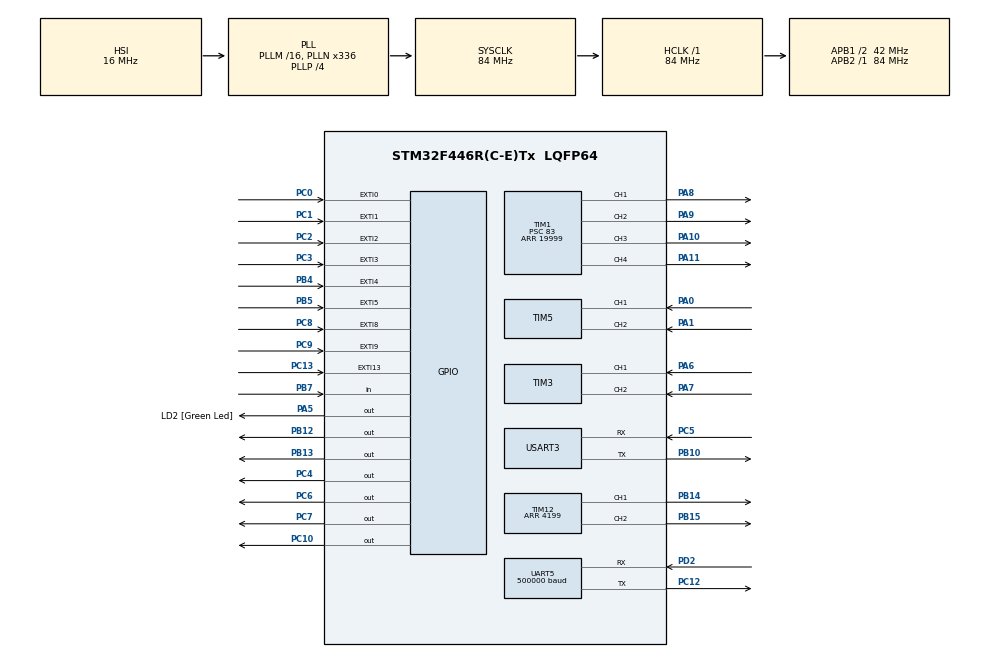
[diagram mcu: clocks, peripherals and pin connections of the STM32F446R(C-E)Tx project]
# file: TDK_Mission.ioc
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Dma.Request0=USART3_RX
Dma.Request1=USART3_TX
Dma.USART3_RX.0.Direction=DMA_PERIPH_TO_MEMORY
Dma.USART3_RX.0.FIFOMode=DMA_FIFOMODE_DISABLE
Dma.USART3_RX.0.Instance=DMA1_Stream1
Dma.USART3_RX.0.MemDataAlignment=DMA_MDATAALIGN_BYTE
Dma.USART3_RX.0.MemInc=DMA_MINC_ENABLE
Dma.USART3_RX.0.Mode=DMA_NORMAL
Dma.USART3_RX.0.PeriphDataAlignment=DMA_PDATAALIGN_BYTE
Dma.USART3_RX.0.PeriphInc=DMA_PINC_DISABLE
Dma.USART3_RX.0.Priority=DMA_PRIORITY_LOW
Dma.USART3_TX.1.Direction=DMA_MEMORY_TO_PERIPH
Dma.USART3_TX.1.FIFOMode=DMA_FIFOMODE_DISABLE
Dma.USART3_TX.1.Instance=DMA1_Stream3
Dma.USART3_TX.1.MemDataAlignment=DMA_MDATAALIGN_BYTE
Dma.USART3_TX.1.MemInc=DMA_MINC_ENABLE
Dma.USART3_TX.1.Mode=DMA_NORMAL
Dma.USART3_TX.1.PeriphDataAlignment=DMA_PDATAALIGN_BYTE
Dma.USART3_TX.1.PeriphInc=DMA_PINC_DISABLE
Dma.USART3_TX.1.Priority=DMA_PRIORITY_LOW
Mcu.Family=STM32F4
Mcu.Name=STM32F446R(C-E)Tx
Mcu.Package=LQFP64
NVIC.DMA1_Stream1_IRQn=true\:0\:0\:false\:false\:true\:false\:true\:true
NVIC.DMA1_Stream3_IRQn=true\:0\:0\:false\:false\:true\:false\:true\:true
NVIC.EXTI0_IRQn=true\:0\:0\:true\:true\:true\:1\:true\:true\:true
NVIC.EXTI15_10_IRQn=true\:0\:0\:false\:false\:true\:true\:true\:true
NVIC.EXTI1_IRQn=true\:0\:0\:false\:true\:true\:2\:true\:true\:true
NVIC.EXTI2_IRQn=true\:0\:0\:false\:false\:true\:true\:true\:true
NVIC.EXTI3_IRQn=true\:0\:0\:false\:false\:true\:true\:true\:true
NVIC.EXTI4_IRQn=true\:0\:0\:false\:true\:true\:3\:true\:true\:true
NVIC.EXTI9_5_IRQn=true\:0\:0\:false\:true\:true\:4\:true\:true\:true
NVIC.PriorityGroup=NVIC_PRIORITYGROUP_0
NVIC.TIM1_BRK_TIM9_IRQn=true\:0\:0\:false\:true\:true\:5\:true\:true\:true
NVIC.TIM1_TRG_COM_TIM11_IRQn=true\:0\:0\:false\:false\:true\:true\:true\:true
NVIC.TIM1_UP_TIM10_IRQn=true\:0\:0\:false\:true\:true\:6\:true\:true\:true
NVIC.TIM2_IRQn=true\:0\:0\:false\:false\:true\:true\:true\:true
NVIC.TIM7_IRQn=true\:0\:0\:false\:true\:true\:7\:true\:true\:true
NVIC.TIM8_UP_TIM13_IRQn=true\:0\:0\:false\:false\:true\:true\:true\:true
NVIC.USART3_IRQn=true\:0\:0\:false\:false\:true\:true\:true\:true
PA0-WKUP.Signal=S_TIM5_CH1
PA1.Signal=S_TIM5_CH2
PA10.Signal=S_TIM1_CH3
PA11.Signal=S_TIM1_CH4
PA13.GPIO_Label=TMS
PA13.Mode=Serial_Wire
PA13.Signal=SYS_JTMS-SWDIO
PA14.GPIO_Label=TCK
PA14.Mode=Serial_Wire
PA14.Signal=SYS_JTCK-SWCLK
PA2.Signal=USART2_TX
PA3.Signal=USART2_RX
PA5.GPIO_Label=LD2 [Green Led]
PA5.GPIO_PuPd=GPIO_NOPULL
PA5.Signal=GPIO_Output
PA6.Signal=S_TIM3_CH1
PA7.Signal=S_TIM3_CH2
PA8.Signal=S_TIM1_CH1
PA9.Signal=S_TIM1_CH2
PB10.Mode=Asynchronous
PB10.Signal=USART3_TX
PB12.GPIO_PuPd=GPIO_NOPULL
PB12.Signal=GPIO_Output
PB13.GPIO_PuPd=GPIO_NOPULL
PB13.Signal=GPIO_Output
PB14.Signal=S_TIM12_CH1
PB15.Signal=S_TIM12_CH2
PB3.GPIO_Label=SWO
PB3.Signal=SYS_JTDO-SWO
PB4.GPIO_ModeDefaultEXTI=GPIO_MODE_IT_RISING
PB4.GPIO_PuPd=GPIO_PULLDOWN
PB4.Signal=GPXTI4
PB5.GPIO_ModeDefaultEXTI=GPIO_MODE_IT_RISING
PB5.GPIO_PuPd=GPIO_PULLDOWN
PB5.Signal=GPXTI5
PB7.GPIO_PuPd=GPIO_PULLUP
PB7.Signal=GPIO_Input
PC0.GPIO_ModeDefaultEXTI=GPIO_MODE_IT_RISING
PC0.GPIO_PuPd=GPIO_PULLDOWN
PC0.Signal=GPXTI0
PC1.GPIO_ModeDefaultEXTI=GPIO_MODE_IT_RISING
PC1.GPIO_PuPd=GPIO_PULLDOWN
PC1.Signal=GPXTI1
PC10.Signal=GPIO_Output
PC12.Mode=Asynchronous
PC12.Signal=UART5_TX
PC13.GPIO_ModeDefaultEXTI=GPIO_MODE_IT_FALLING
PC13.GPIO_PuPd=GPIO_PULLUP
PC13.Signal=GPXTI13
PC14-OSC32_IN.Mode=LSE-External-Oscillator
PC14-OSC32_IN.Signal=RCC_OSC32_IN
PC15-OSC32_OUT.Mode=LSE-External-Oscillator
PC15-OSC32_OUT.Signal=RCC_OSC32_OUT
PC2.GPIO_ModeDefaultEXTI=GPIO_MODE_IT_FALLING
PC2.GPIO_PuPd=GPIO_PULLUP
PC2.Signal=GPXTI2
PC3.GPIO_ModeDefaultEXTI=GPIO_MODE_IT_FALLING
PC3.GPIO_PuPd=GPIO_PULLUP
PC3.Signal=GPXTI3
PC4.Signal=GPIO_Output
PC5.Mode=Asynchronous
PC5.Signal=USART3_RX
PC6.Signal=GPIO_Output
PC7.Signal=GPIO_Output
PC8.GPIO_ModeDefaultEXTI=GPIO_MODE_IT_FALLING
PC8.GPIO_PuPd=GPIO_PULLUP
PC8.Signal=GPXTI8
PC9.Signal=GPXTI9
PD2.Mode=Asynchronous
PD2.Signal=UART5_RX
PH0-OSC_IN.Mode=HSE-External-Oscillator
PH0-OSC_IN.Signal=RCC_OSC_IN
PH1-OSC_OUT.Mode=HSE-External-Oscillator
PH1-OSC_OUT.Signal=RCC_OSC_OUT
ProjectManager.HeapSize=0x200
ProjectManager.StackSize=0x400
ProjectManager.TargetToolchain=STM32CubeIDE
RCC.48MHZClocksFreq_Value=84000000
RCC.AHBFreq_Value=84000000
RCC.APB1CLKDivider=RCC_HCLK_DIV2
RCC.APB1Freq_Value=42000000
RCC.APB1TimFreq_Value=84000000
RCC.APB2Freq_Value=84000000
RCC.APB2TimFreq_Value=84000000
RCC.CortexFreq_Value=84000000
RCC.FLatency-AdvancedSettings=FLASH_LATENCY_2
RCC.HCLKFreq_Value=84000000
RCC.HSE_VALUE=8000000
RCC.HSI_VALUE=16000000
RCC.PLLN=336
RCC.PLLP=RCC_PLLP_DIV4
RCC.SYSCLKFreq_VALUE=84000000
RCC.SYSCLKSource=RCC_SYSCLKSOURCE_PLLCLK
RCC.USBFreq_Value=168000000
RCC.VCOOutputFreq_Value=336000000
SH.S_TIM12_CH1.0=TIM12_CH1,PWM Generation1 CH1
SH.S_TIM12_CH2.0=TIM12_CH2,PWM Generation2 CH2
SH.S_TIM1_CH1.0=TIM1_CH1,PWM Generation1 CH1
SH.S_TIM1_CH2.0=TIM1_CH2,PWM Generation2 CH2
SH.S_TIM1_CH3.0=TIM1_CH3,PWM Generation3 CH3
SH.S_TIM1_CH4.0=TIM1_CH4,PWM Generation4 CH4
SH.S_TIM3_CH1.0=TIM3_CH1,Encoder_Interface
SH.S_TIM3_CH2.0=TIM3_CH2,Encoder_Interface
SH.S_TIM5_CH1.0=TIM5_CH1,Encoder_Interface
SH.S_TIM5_CH2.0=TIM5_CH2,Encoder_Interface
TIM1.Channel-PWM\ Generation1\ CH1=TIM_CHANNEL_1
TIM1.Channel-PWM\ Generation2\ CH2=TIM_CHANNEL_2
TIM1.Channel-PWM\ Generation3\ CH3=TIM_CHANNEL_3
TIM1.Channel-PWM\ Generation4\ CH4=TIM_CHANNEL_4
TIM1.Period=19999
TIM1.Prescaler=83
TIM10.Period=999
TIM10.Prescaler=83
TIM11.Period=999
TIM11.Prescaler=83
TIM12.Channel-PWM\ Generation1\ CH1=TIM_CHANNEL_1
TIM12.Channel-PWM\ Generation2\ CH2=TIM_CHANNEL_2
TIM12.Period=4199
TIM12.Pulse-PWM\ Generation1\ CH1=4000
TIM12.Pulse-PWM\ Generation2\ CH2=4000
TIM13.Period=999
TIM13.Prescaler=83
TIM2.Period=99999
TIM2.Prescaler=83
TIM3.EncoderMode=TIM_ENCODERMODE_TI12
TIM5.EncoderMode=TIM_ENCODERMODE_TI12
TIM7.Period=999
TIM7.Prescaler=83
TIM9.Period=999
TIM9.Prescaler=83
UART5.BaudRate=500000
UART5.VirtualMode=Asynchronous
USART3.VirtualMode=VM_ASYNC
VP_TIM10_VS_ClockSourceINT.Mode=Enable_Timer
VP_TIM11_VS_ClockSourceINT.Mode=Enable_Timer
VP_TIM13_VS_ClockSourceINT.Mode=Enable_Timer
VP_TIM2_VS_ClockSourceINT.Mode=Internal
VP_TIM7_VS_ClockSourceINT.Mode=Enable_Timer
VP_TIM9_VS_ClockSourceINT.Mode=Internal
board=NUCLEO-F446RE

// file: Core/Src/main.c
/* USER CODE BEGIN Header */
/**
  ******************************************************************************
  * @file           : main.c
  * @brief          : Main program body
  ******************************************************************************
  * @attention
  *
  * Copyright (c) 2024 STMicroelectronics.
  * All rights reserved.
  *
  * This software is licensed under terms that can be found in the LICENSE file
  * in the root directory of this software component.
  * If no LICENSE file comes with this software, it is provided AS-IS.
  *
  ******************************************************************************
  */
/* USER CODE END Header */
#include "main.h"

/* USER CODE BEGIN Includes */
#include "mainpp.h"
/* USER CODE END Includes */

TIM_HandleTypeDef htim1;
TIM_HandleTypeDef htim2;
TIM_HandleTypeDef htim3;
TIM_HandleTypeDef htim5;
TIM_HandleTypeDef htim7;
TIM_HandleTypeDef htim9;
TIM_HandleTypeDef htim10;
TIM_HandleTypeDef htim11;
TIM_HandleTypeDef htim12;
TIM_HandleTypeDef htim13;

UART_HandleTypeDef huart5;
UART_HandleTypeDef huart3;
DMA_HandleTypeDef hdma_usart3_rx;
DMA_HandleTypeDef hdma_usart3_tx;

void SystemClock_Config(void);
static void MX_GPIO_Init(void);
static void MX_DMA_Init(void);
static void MX_TIM1_Init(void);
static void MX_TIM3_Init(void);
static void MX_TIM7_Init(void);
static void MX_UART5_Init(void);
static void MX_USART3_UART_Init(void);
static void MX_TIM12_Init(void);
static void MX_TIM10_Init(void);
static void MX_TIM11_Init(void);
static void MX_TIM5_Init(void);
static void MX_TIM2_Init(void);
static void MX_TIM9_Init(void);
static void MX_TIM13_Init(void);
static void MX_NVIC_Init(void);

/* USER CODE BEGIN 0 */
int q = 0;
/* USER CODE END 0 */

int main(void)
{

  /* MCU Configuration--------------------------------------------------------*/

  /* Reset of all peripherals, Initializes the Flash interface and the Systick. */
  HAL_Init();

  /* Configure the system clock */
  SystemClock_Config();

  /* Initialize all configured peripherals */
  MX_GPIO_Init();
  MX_DMA_Init();
  MX_TIM1_Init();
  MX_TIM3_Init();
  MX_TIM7_Init();
  MX_UART5_Init();
  MX_USART3_UART_Init();
  MX_TIM12_Init();
  MX_TIM10_Init();
  MX_TIM11_Init();
  MX_TIM5_Init();
  MX_TIM2_Init();
  MX_TIM9_Init();
  MX_TIM13_Init();

  /* Initialize interrupts */
  MX_NVIC_Init();
  /* USER CODE BEGIN 2 */
  setup();

  main_function();

  /* USER CODE END 2 */

  /* Infinite loop */
  while (1)
  {

  }
}

void SystemClock_Config(void)
{
  RCC_OscInitTypeDef RCC_OscInitStruct = {0};
  RCC_ClkInitTypeDef RCC_ClkInitStruct = {0};

  /** Configure the main internal regulator output voltage
  */
  __HAL_RCC_PWR_CLK_ENABLE();
  __HAL_PWR_VOLTAGESCALING_CONFIG(PWR_REGULATOR_VOLTAGE_SCALE3);

  /** Initializes the RCC Oscillators according to the specified parameters
  * in the RCC_OscInitTypeDef structure.
  */
  RCC_OscInitStruct.OscillatorType = RCC_OSCILLATORTYPE_HSI;
  RCC_OscInitStruct.HSIState = RCC_HSI_ON;
  RCC_OscInitStruct.HSICalibrationValue = RCC_HSICALIBRATION_DEFAULT;
  RCC_OscInitStruct.PLL.PLLState = RCC_PLL_ON;
  RCC_OscInitStruct.PLL.PLLSource = RCC_PLLSOURCE_HSI;
  RCC_OscInitStruct.PLL.PLLM = 16;
  RCC_OscInitStruct.PLL.PLLN = 336;
  RCC_OscInitStruct.PLL.PLLP = RCC_PLLP_DIV4;
  RCC_OscInitStruct.PLL.PLLQ = 2;
  RCC_OscInitStruct.PLL.PLLR = 2;
  if (HAL_RCC_OscConfig(&RCC_OscInitStruct) != HAL_OK)
  {
    Error_Handler();
  }

  /** Initializes the CPU, AHB and APB buses clocks
  */
  RCC_ClkInitStruct.ClockType = RCC_CLOCKTYPE_HCLK|RCC_CLOCKTYPE_SYSCLK
                              |RCC_CLOCKTYPE_PCLK1|RCC_CLOCKTYPE_PCLK2;
  RCC_ClkInitStruct.SYSCLKSource = RCC_SYSCLKSOURCE_PLLCLK;
  RCC_ClkInitStruct.AHBCLKDivider = RCC_SYSCLK_DIV1;
  RCC_ClkInitStruct.APB1CLKDivider = RCC_HCLK_DIV2;
  RCC_ClkInitStruct.APB2CLKDivider = RCC_HCLK_DIV1;

  if (HAL_RCC_ClockConfig(&RCC_ClkInitStruct, FLASH_LATENCY_2) != HAL_OK)
  {
    Error_Handler();
  }
}

/**
  * @brief NVIC Configuration.
  * @retval None
  */
static void MX_NVIC_Init(void)
{
  /* EXTI0_IRQn interrupt configuration */
  HAL_NVIC_SetPriority(EXTI0_IRQn, 0, 0);
  HAL_NVIC_EnableIRQ(EXTI0_IRQn);
  /* EXTI1_IRQn interrupt configuration */
  HAL_NVIC_SetPriority(EXTI1_IRQn, 0, 0);
  HAL_NVIC_EnableIRQ(EXTI1_IRQn);
  /* EXTI4_IRQn interrupt configuration */
  HAL_NVIC_SetPriority(EXTI4_IRQn, 0, 0);
  HAL_NVIC_EnableIRQ(EXTI4_IRQn);
  /* EXTI9_5_IRQn interrupt configuration */
  HAL_NVIC_SetPriority(EXTI9_5_IRQn, 0, 0);
  HAL_NVIC_EnableIRQ(EXTI9_5_IRQn);
  /* TIM1_BRK_TIM9_IRQn interrupt configuration */
  HAL_NVIC_SetPriority(TIM1_BRK_TIM9_IRQn, 0, 0);
  HAL_NVIC_EnableIRQ(TIM1_BRK_TIM9_IRQn);
  /* TIM1_UP_TIM10_IRQn interrupt configuration */
  HAL_NVIC_SetPriority(TIM1_UP_TIM10_IRQn, 0, 0);
  HAL_NVIC_EnableIRQ(TIM1_UP_TIM10_IRQn);
  /* TIM7_IRQn interrupt configuration */
  HAL_NVIC_SetPriority(TIM7_IRQn, 0, 0);
  HAL_NVIC_EnableIRQ(TIM7_IRQn);
}

static void MX_TIM1_Init(void)
{

  TIM_MasterConfigTypeDef sMasterConfig = {0};
  TIM_OC_InitTypeDef sConfigOC = {0};
  TIM_BreakDeadTimeConfigTypeDef sBreakDeadTimeConfig = {0};

  htim1.Instance = TIM1;
  htim1.Init.Prescaler = 83;
  htim1.Init.CounterMode = TIM_COUNTERMODE_UP;
  htim1.Init.Period = 19999;
  htim1.Init.ClockDivision = TIM_CLOCKDIVISION_DIV1;
  htim1.Init.RepetitionCounter = 0;
  htim1.Init.AutoReloadPreload = TIM_AUTORELOAD_PRELOAD_DISABLE;
  if (HAL_TIM_PWM_Init(&htim1) != HAL_OK)
  {
    Error_Handler();
  }
  sMasterConfig.MasterOutputTrigger = TIM_TRGO_RESET;
  sMasterConfig.MasterSlaveMode = TIM_MASTERSLAVEMODE_DISABLE;
  if (HAL_TIMEx_MasterConfigSynchronization(&htim1, &sMasterConfig) != HAL_OK)
  {
    Error_Handler();
  }
  sConfigOC.OCMode = TIM_OCMODE_PWM1;
  sConfigOC.Pulse = 0;
  sConfigOC.OCPolarity = TIM_OCPOLARITY_HIGH;
  sConfigOC.OCNPolarity = TIM_OCNPOLARITY_HIGH;
  sConfigOC.OCFastMode = TIM_OCFAST_DISABLE;
  sConfigOC.OCIdleState = TIM_OCIDLESTATE_RESET;
  sConfigOC.OCNIdleState = TIM_OCNIDLESTATE_RESET;
  if (HAL_TIM_PWM_ConfigChannel(&htim1, &sConfigOC, TIM_CHANNEL_1) != HAL_OK)
  {
    Error_Handler();
  }
  if (HAL_TIM_PWM_ConfigChannel(&htim1, &sConfigOC, TIM_CHANNEL_2) != HAL_OK)
  {
    Error_Handler();
  }
  if (HAL_TIM_PWM_ConfigChannel(&htim1, &sConfigOC, TIM_CHANNEL_3) != HAL_OK)
  {
    Error_Handler();
  }
  if (HAL_TIM_PWM_ConfigChannel(&htim1, &sConfigOC, TIM_CHANNEL_4) != HAL_OK)
  {
    Error_Handler();
  }
  sBreakDeadTimeConfig.OffStateRunMode = TIM_OSSR_DISABLE;
  sBreakDeadTimeConfig.OffStateIDLEMode = TIM_OSSI_DISABLE;
  sBreakDeadTimeConfig.LockLevel = TIM_LOCKLEVEL_OFF;
  sBreakDeadTimeConfig.DeadTime = 0;
  sBreakDeadTimeConfig.BreakState = TIM_BREAK_DISABLE;
  sBreakDeadTimeConfig.BreakPolarity = TIM_BREAKPOLARITY_HIGH;
  sBreakDeadTimeConfig.AutomaticOutput = TIM_AUTOMATICOUTPUT_DISABLE;
  if (HAL_TIMEx_ConfigBreakDeadTime(&htim1, &sBreakDeadTimeConfig) != HAL_OK)
  {
    Error_Handler();
  }
  HAL_TIM_MspPostInit(&htim1);

}

static void MX_TIM2_Init(void)
{

  TIM_ClockConfigTypeDef sClockSourceConfig = {0};
  TIM_MasterConfigTypeDef sMasterConfig = {0};

  htim2.Instance = TIM2;
  htim2.Init.Prescaler = 83;
  htim2.Init.CounterMode = TIM_COUNTERMODE_UP;
  htim2.Init.Period = 99999;
  htim2.Init.ClockDivision = TIM_CLOCKDIVISION_DIV1;
  htim2.Init.AutoReloadPreload = TIM_AUTORELOAD_PRELOAD_DISABLE;
  if (HAL_TIM_Base_Init(&htim2) != HAL_OK)
  {
    Error_Handler();
  }
  sClockSourceConfig.ClockSource = TIM_CLOCKSOURCE_INTERNAL;
  if (HAL_TIM_ConfigClockSource(&htim2, &sClockSourceConfig) != HAL_OK)
  {
    Error_Handler();
  }
  sMasterConfig.MasterOutputTrigger = TIM_TRGO_RESET;
  sMasterConfig.MasterSlaveMode = TIM_MASTERSLAVEMODE_DISABLE;
  if (HAL_TIMEx_MasterConfigSynchronization(&htim2, &sMasterConfig) != HAL_OK)
  {
    Error_Handler();
  }

}

static void MX_TIM3_Init(void)
{

  TIM_Encoder_InitTypeDef sConfig = {0};
  TIM_MasterConfigTypeDef sMasterConfig = {0};

  htim3.Instance = TIM3;
  htim3.Init.Prescaler = 0;
  htim3.Init.CounterMode = TIM_COUNTERMODE_UP;
  htim3.Init.Period = 65535;
  htim3.Init.ClockDivision = TIM_CLOCKDIVISION_DIV1;
  htim3.Init.AutoReloadPreload = TIM_AUTORELOAD_PRELOAD_DISABLE;
  sConfig.EncoderMode = TIM_ENCODERMODE_TI12;
  sConfig.IC1Polarity = TIM_ICPOLARITY_RISING;
  sConfig.IC1Selection = TIM_ICSELECTION_DIRECTTI;
  sConfig.IC1Prescaler = TIM_ICPSC_DIV1;
  sConfig.IC1Filter = 0;
  sConfig.IC2Polarity = TIM_ICPOLARITY_RISING;
  sConfig.IC2Selection = TIM_ICSELECTION_DIRECTTI;
  sConfig.IC2Prescaler = TIM_ICPSC_DIV1;
  sConfig.IC2Filter = 0;
  if (HAL_TIM_Encoder_Init(&htim3, &sConfig) != HAL_OK)
  {
    Error_Handler();
  }
  sMasterConfig.MasterOutputTrigger = TIM_TRGO_RESET;
  sMasterConfig.MasterSlaveMode = TIM_MASTERSLAVEMODE_DISABLE;
  if (HAL_TIMEx_MasterConfigSynchronization(&htim3, &sMasterConfig) != HAL_OK)
  {
    Error_Handler();
  }

}

static void MX_TIM5_Init(void)
{

  TIM_Encoder_InitTypeDef sConfig = {0};
  TIM_MasterConfigTypeDef sMasterConfig = {0};

  htim5.Instance = TIM5;
  htim5.Init.Prescaler = 0;
  htim5.Init.CounterMode = TIM_COUNTERMODE_UP;
  htim5.Init.Period = 4294967295;
  htim5.Init.ClockDivision = TIM_CLOCKDIVISION_DIV1;
  htim5.Init.AutoReloadPreload = TIM_AUTORELOAD_PRELOAD_DISABLE;
  sConfig.EncoderMode = TIM_ENCODERMODE_TI12;
  sConfig.IC1Polarity = TIM_ICPOLARITY_RISING;
  sConfig.IC1Selection = TIM_ICSELECTION_DIRECTTI;
  sConfig.IC1Prescaler = TIM_ICPSC_DIV1;
  sConfig.IC1Filter = 0;
  sConfig.IC2Polarity = TIM_ICPOLARITY_RISING;
  sConfig.IC2Selection = TIM_ICSELECTION_DIRECTTI;
  sConfig.IC2Prescaler = TIM_ICPSC_DIV1;
  sConfig.IC2Filter = 0;
  if (HAL_TIM_Encoder_Init(&htim5, &sConfig) != HAL_OK)
  {
    Error_Handler();
  }
  sMasterConfig.MasterOutputTrigger = TIM_TRGO_RESET;
  sMasterConfig.MasterSlaveMode = TIM_MASTERSLAVEMODE_DISABLE;
  if (HAL_TIMEx_MasterConfigSynchronization(&htim5, &sMasterConfig) != HAL_OK)
  {
    Error_Handler();
  }

}

static void MX_TIM7_Init(void)
{

  TIM_MasterConfigTypeDef sMasterConfig = {0};

  htim7.Instance = TIM7;
  htim7.Init.Prescaler = 83;
  htim7.Init.CounterMode = TIM_COUNTERMODE_UP;
  htim7.Init.Period = 999;
  htim7.Init.AutoReloadPreload = TIM_AUTORELOAD_PRELOAD_DISABLE;
  if (HAL_TIM_Base_Init(&htim7) != HAL_OK)
  {
    Error_Handler();
  }
  sMasterConfig.MasterOutputTrigger = TIM_TRGO_RESET;
  sMasterConfig.MasterSlaveMode = TIM_MASTERSLAVEMODE_DISABLE;
  if (HAL_TIMEx_MasterConfigSynchronization(&htim7, &sMasterConfig) != HAL_OK)
  {
    Error_Handler();
  }

}

static void MX_TIM9_Init(void)
{

  TIM_ClockConfigTypeDef sClockSourceConfig = {0};

  htim9.Instance = TIM9;
  htim9.Init.Prescaler = 83;
  htim9.Init.CounterMode = TIM_COUNTERMODE_UP;
  htim9.Init.Period = 999;
  htim9.Init.ClockDivision = TIM_CLOCKDIVISION_DIV1;
  htim9.Init.AutoReloadPreload = TIM_AUTORELOAD_PRELOAD_DISABLE;
  if (HAL_TIM_Base_Init(&htim9) != HAL_OK)
  {
    Error_Handler();
  }
  sClockSourceConfig.ClockSource = TIM_CLOCKSOURCE_INTERNAL;
  if (HAL_TIM_ConfigClockSource(&htim9, &sClockSourceConfig) != HAL_OK)
  {
    Error_Handler();
  }

}

static void MX_TIM10_Init(void)
{

  htim10.Instance = TIM10;
  htim10.Init.Prescaler = 83;
  htim10.Init.CounterMode = TIM_COUNTERMODE_UP;
  htim10.Init.Period = 999;
  htim10.Init.ClockDivision = TIM_CLOCKDIVISION_DIV1;
  htim10.Init.AutoReloadPreload = TIM_AUTORELOAD_PRELOAD_DISABLE;
  if (HAL_TIM_Base_Init(&htim10) != HAL_OK)
  {
    Error_Handler();
  }

}

static void MX_TIM11_Init(void)
{

  htim11.Instance = TIM11;
  htim11.Init.Prescaler = 83;
  htim11.Init.CounterMode = TIM_COUNTERMODE_UP;
  htim11.Init.Period = 999;
  htim11.Init.ClockDivision = TIM_CLOCKDIVISION_DIV1;
  htim11.Init.AutoReloadPreload = TIM_AUTORELOAD_PRELOAD_DISABLE;
  if (HAL_TIM_Base_Init(&htim11) != HAL_OK)
  {
    Error_Handler();
  }

}

static void MX_TIM12_Init(void)
{

  TIM_OC_InitTypeDef sConfigOC = {0};

  htim12.Instance = TIM12;
  htim12.Init.Prescaler = 0;
  htim12.Init.CounterMode = TIM_COUNTERMODE_UP;
  htim12.Init.Period = 4199;
  htim12.Init.ClockDivision = TIM_CLOCKDIVISION_DIV1;
  htim12.Init.AutoReloadPreload = TIM_AUTORELOAD_PRELOAD_DISABLE;
  if (HAL_TIM_PWM_Init(&htim12) != HAL_OK)
  {
    Error_Handler();
  }
  sConfigOC.OCMode = TIM_OCMODE_PWM1;
  sConfigOC.Pulse = 4000;
  sConfigOC.OCPolarity = TIM_OCPOLARITY_HIGH;
  sConfigOC.OCFastMode = TIM_OCFAST_DISABLE;
  if (HAL_TIM_PWM_ConfigChannel(&htim12, &sConfigOC, TIM_CHANNEL_1) != HAL_OK)
  {
    Error_Handler();
  }
  if (HAL_TIM_PWM_ConfigChannel(&htim12, &sConfigOC, TIM_CHANNEL_2) != HAL_OK)
  {
    Error_Handler();
  }
  HAL_TIM_MspPostInit(&htim12);

}

static void MX_TIM13_Init(void)
{

  htim13.Instance = TIM13;
  htim13.Init.Prescaler = 83;
  htim13.Init.CounterMode = TIM_COUNTERMODE_UP;
  htim13.Init.Period = 999;
  htim13.Init.ClockDivision = TIM_CLOCKDIVISION_DIV1;
  htim13.Init.AutoReloadPreload = TIM_AUTORELOAD_PRELOAD_DISABLE;
  if (HAL_TIM_Base_Init(&htim13) != HAL_OK)
  {
    Error_Handler();
  }

}

static void MX_UART5_Init(void)
{

  huart5.Instance = UART5;
  huart5.Init.BaudRate = 500000;
  huart5.Init.WordLength = UART_WORDLENGTH_8B;
  huart5.Init.StopBits = UART_STOPBITS_1;
  huart5.Init.Parity = UART_PARITY_NONE;
  huart5.Init.Mode = UART_MODE_TX_RX;
  huart5.Init.HwFlowCtl = UART_HWCONTROL_NONE;
  huart5.Init.OverSampling = UART_OVERSAMPLING_16;
  if (HAL_UART_Init(&huart5) != HAL_OK)
  {
    Error_Handler();
  }

}

static void MX_USART3_UART_Init(void)
{

  huart3.Instance = USART3;
  huart3.Init.BaudRate = 115200;
  huart3.Init.WordLength = UART_WORDLENGTH_8B;
  huart3.Init.StopBits = UART_STOPBITS_1;
  huart3.Init.Parity = UART_PARITY_NONE;
  huart3.Init.Mode = UART_MODE_TX_RX;
  huart3.Init.HwFlowCtl = UART_HWCONTROL_NONE;
  huart3.Init.OverSampling = UART_OVERSAMPLING_16;
  if (HAL_UART_Init(&huart3) != HAL_OK)
  {
    Error_Handler();
  }

}

static void MX_DMA_Init(void)
{

  /* DMA controller clock enable */
  __HAL_RCC_DMA1_CLK_ENABLE();

  /* DMA interrupt init */
  /* DMA1_Stream1_IRQn interrupt configuration */
  HAL_NVIC_SetPriority(DMA1_Stream1_IRQn, 0, 0);
  HAL_NVIC_EnableIRQ(DMA1_Stream1_IRQn);
  /* DMA1_Stream3_IRQn interrupt configuration */
  HAL_NVIC_SetPriority(DMA1_Stream3_IRQn, 0, 0);
  HAL_NVIC_EnableIRQ(DMA1_Stream3_IRQn);

}

static void MX_GPIO_Init(void)
{
  GPIO_InitTypeDef GPIO_InitStruct = {0};

  /* GPIO Ports Clock Enable */
  __HAL_RCC_GPIOC_CLK_ENABLE();
  __HAL_RCC_GPIOH_CLK_ENABLE();
  __HAL_RCC_GPIOA_CLK_ENABLE();
  __HAL_RCC_GPIOB_CLK_ENABLE();
  __HAL_RCC_GPIOD_CLK_ENABLE();

  /*Configure GPIO pin Output Level */
  HAL_GPIO_WritePin(LD2_GPIO_Port, LD2_Pin, GPIO_PIN_RESET);

  /*Configure GPIO pin Output Level */
  HAL_GPIO_WritePin(GPIOC, GPIO_PIN_4|GPIO_PIN_6|GPIO_PIN_7|GPIO_PIN_10, GPIO_PIN_RESET);

  /*Configure GPIO pin Output Level */
  HAL_GPIO_WritePin(GPIOB, GPIO_PIN_12|GPIO_PIN_13, GPIO_PIN_RESET);

  /*Configure GPIO pins : PC13 PC2 PC3 PC8 */
  GPIO_InitStruct.Pin = GPIO_PIN_13|GPIO_PIN_2|GPIO_PIN_3|GPIO_PIN_8;
  GPIO_InitStruct.Mode = GPIO_MODE_IT_FALLING;
  GPIO_InitStruct.Pull = GPIO_PULLUP;
  HAL_GPIO_Init(GPIOC, &GPIO_InitStruct);

  /*Configure GPIO pins : PC0 PC1 */
  GPIO_InitStruct.Pin = GPIO_PIN_0|GPIO_PIN_1;
  GPIO_InitStruct.Mode = GPIO_MODE_IT_RISING;
  GPIO_InitStruct.Pull = GPIO_PULLDOWN;
  HAL_GPIO_Init(GPIOC, &GPIO_InitStruct);

  /*Configure GPIO pins : PA2 PA3 */
  GPIO_InitStruct.Pin = GPIO_PIN_2|GPIO_PIN_3;
  GPIO_InitStruct.Mode = GPIO_MODE_AF_PP;
  GPIO_InitStruct.Pull = GPIO_NOPULL;
  GPIO_InitStruct.Speed = GPIO_SPEED_FREQ_VERY_HIGH;
  GPIO_InitStruct.Alternate = GPIO_AF7_USART2;
  HAL_GPIO_Init(GPIOA, &GPIO_InitStruct);

  /*Configure GPIO pin : LD2_Pin */
  GPIO_InitStruct.Pin = LD2_Pin;
  GPIO_InitStruct.Mode = GPIO_MODE_OUTPUT_PP;
  GPIO_InitStruct.Pull = GPIO_NOPULL;
  GPIO_InitStruct.Speed = GPIO_SPEED_FREQ_LOW;
  HAL_GPIO_Init(LD2_GPIO_Port, &GPIO_InitStruct);

  /*Configure GPIO pins : PC4 PC6 PC7 PC10 */
  GPIO_InitStruct.Pin = GPIO_PIN_4|GPIO_PIN_6|GPIO_PIN_7|GPIO_PIN_10;
  GPIO_InitStruct.Mode = GPIO_MODE_OUTPUT_PP;
  GPIO_InitStruct.Pull = GPIO_NOPULL;
  GPIO_InitStruct.Speed = GPIO_SPEED_FREQ_LOW;
  HAL_GPIO_Init(GPIOC, &GPIO_InitStruct);

  /*Configure GPIO pins : PB12 PB13 */
  GPIO_InitStruct.Pin = GPIO_PIN_12|GPIO_PIN_13;
  GPIO_InitStruct.Mode = GPIO_MODE_OUTPUT_PP;
  GPIO_InitStruct.Pull = GPIO_NOPULL;
  GPIO_InitStruct.Speed = GPIO_SPEED_FREQ_LOW;
  HAL_GPIO_Init(GPIOB, &GPIO_InitStruct);

  /*Configure GPIO pin : PC9 */
  GPIO_InitStruct.Pin = GPIO_PIN_9;
  GPIO_InitStruct.Mode = GPIO_MODE_IT_RISING;
  GPIO_InitStruct.Pull = GPIO_NOPULL;
  HAL_GPIO_Init(GPIOC, &GPIO_InitStruct);

  /*Configure GPIO pins : PB4 PB5 */
  GPIO_InitStruct.Pin = GPIO_PIN_4|GPIO_PIN_5;
  GPIO_InitStruct.Mode = GPIO_MODE_IT_RISING;
  GPIO_InitStruct.Pull = GPIO_PULLDOWN;
  HAL_GPIO_Init(GPIOB, &GPIO_InitStruct);

  /*Configure GPIO pin : PB7 */
  GPIO_InitStruct.Pin = GPIO_PIN_7;
  GPIO_InitStruct.Mode = GPIO_MODE_INPUT;
  GPIO_InitStruct.Pull = GPIO_PULLUP;
  HAL_GPIO_Init(GPIOB, &GPIO_InitStruct);

  /* EXTI interrupt init*/
  HAL_NVIC_SetPriority(EXTI2_IRQn, 0, 0);
  HAL_NVIC_EnableIRQ(EXTI2_IRQn);

  HAL_NVIC_SetPriority(EXTI3_IRQn, 0, 0);
  HAL_NVIC_EnableIRQ(EXTI3_IRQn);

  HAL_NVIC_SetPriority(EXTI15_10_IRQn, 0, 0);
  HAL_NVIC_EnableIRQ(EXTI15_10_IRQn);

}

void Error_Handler(void)
{
  __disable_irq();
  while (1)
  {
  }
}
